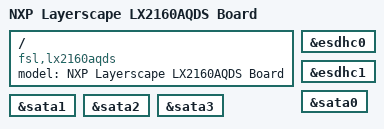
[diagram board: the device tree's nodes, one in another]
// SPDX-License-Identifier: GPL-2.0+ OR X11
/*
 * NXP LX2160AQDS device tree source
 *
 * Copyright 2018-2019 NXP
 *
 */

/dts-v1/;

#include "fsl-lx2160a.dtsi"

/ {
	model = "NXP Layerscape LX2160AQDS Board";
	compatible = "fsl,lx2160aqds", "fsl,lx2160a";
};

&esdhc0 {
	status = "okay";
};

&esdhc1 {
	status = "okay";
};

&sata0 {
	status = "okay";
};

&sata1 {
	status = "okay";
};

&sata2 {
	status = "okay";
};

&sata3 {
	status = "okay";
};
